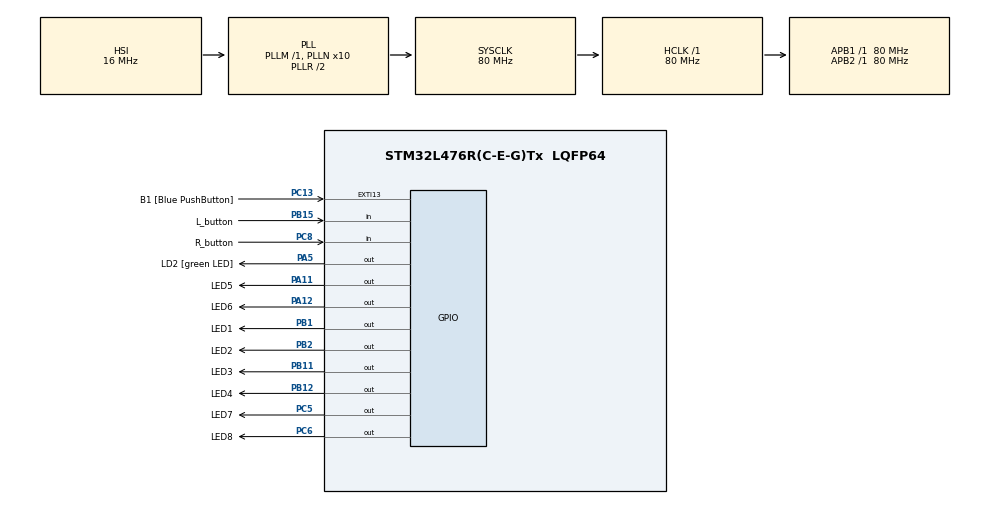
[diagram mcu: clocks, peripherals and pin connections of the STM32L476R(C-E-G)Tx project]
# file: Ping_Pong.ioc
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Mcu.Family=STM32L4
Mcu.Name=STM32L476R(C-E-G)Tx
Mcu.Package=LQFP64
NVIC.PriorityGroup=NVIC_PRIORITYGROUP_4
PA11.GPIO_Label=LED5
PA11.Signal=GPIO_Output
PA12.GPIO_Label=LED6
PA12.Signal=GPIO_Output
PA13\ (JTMS-SWDIO).GPIO_Label=TMS
PA13\ (JTMS-SWDIO).Signal=SYS_JTMS-SWDIO
PA14\ (JTCK-SWCLK).GPIO_Label=TCK
PA14\ (JTCK-SWCLK).Signal=SYS_JTCK-SWCLK
PA5.GPIO_Label=LD2 [green LED]
PA5.Signal=GPIO_Output
PB1.GPIO_Label=LED1
PB1.Signal=GPIO_Output
PB11.GPIO_Label=LED3
PB11.Signal=GPIO_Output
PB12.GPIO_Label=LED4
PB12.Signal=GPIO_Output
PB15.GPIO_Label=L_button
PB15.GPIO_PuPd=GPIO_PULLUP
PB15.Signal=GPIO_Input
PB2.GPIO_Label=LED2
PB2.Signal=GPIO_Output
PB3\ (JTDO-TRACESWO).GPIO_Label=SWD
PB3\ (JTDO-TRACESWO).Signal=SYS_JTDO-SWO
PC13.GPIO_Label=B1 [Blue PushButton]
PC13.Signal=GPXTI13
PC14-OSC32_IN\ (PC14).Mode=LSE-External-Oscillator
PC14-OSC32_IN\ (PC14).Signal=RCC_OSC32_IN
PC15-OSC32_OUT\ (PC15).Mode=LSE-External-Oscillator
PC15-OSC32_OUT\ (PC15).Signal=RCC_OSC32_OUT
PC5.GPIO_Label=LED7
PC5.Signal=GPIO_Output
PC6.GPIO_Label=LED8
PC6.Signal=GPIO_Output
PC8.GPIO_Label=R_button
PC8.GPIO_PuPd=GPIO_PULLUP
PC8.Signal=GPIO_Input
PH0-OSC_IN\ (PH0).Mode=HSE-External-Oscillator
PH0-OSC_IN\ (PH0).Signal=RCC_OSC_IN
PH1-OSC_OUT\ (PH1).Mode=HSE-External-Oscillator
PH1-OSC_OUT\ (PH1).Signal=RCC_OSC_OUT
ProjectManager.HeapSize=0x200
ProjectManager.StackSize=0x400
ProjectManager.TargetToolchain=STM32CubeIDE
RCC.ADCFreq_Value=64000000
RCC.AHBFreq_Value=80000000
RCC.APB1Freq_Value=80000000
RCC.APB1TimFreq_Value=80000000
RCC.APB2Freq_Value=80000000
RCC.APB2TimFreq_Value=80000000
RCC.CortexFreq_Value=80000000
RCC.HCLKFreq_Value=80000000
RCC.HSE_VALUE=8000000
RCC.HSI_VALUE=16000000
RCC.MSI_VALUE=4000000
RCC.PLLN=10
RCC.PLLSourceVirtual=RCC_PLLSOURCE_HSI
RCC.SYSCLKFreq_VALUE=80000000
RCC.SYSCLKSource=RCC_SYSCLKSOURCE_PLLCLK
RCC.USBFreq_Value=64000000
RCC.VCOOutputFreq_Value=160000000
board=custom

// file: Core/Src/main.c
/* USER CODE BEGIN Header */
/**
  ******************************************************************************
  * @file           : main.c
  * @brief          : Main program body
  ******************************************************************************
  * @attention
  *
  * Copyright (c) 2024 STMicroelectronics.
  * All rights reserved.
  *
  * This software is licensed under terms that can be found in the LICENSE file
  * in the root directory of this software component.
  * If no LICENSE file comes with this software, it is provided AS-IS.
  *
  ******************************************************************************
  */
/* USER CODE END Header */
#include "main.h"
#include "gpio.h"

/* USER CODE BEGIN Includes */
#include "Pingpong.h"
#include "pingpong_functions.h"
#include "Test.h"
#include <stdbool.h>
/* USER CODE END Includes */

/* USER CODE BEGIN PD */
#define RUN_TEST_PROGRAM
/* USER CODE END PD */

void SystemClock_Config(void);

/* USER CODE BEGIN 0 */
#ifdef Run_TEST_PROGRAM
extern void initialise_monitor_handles(void);
#endif
/* USER CODE END 0 */

int main(void)
{

  /* USER CODE BEGIN 1 */
#undef RUN_TEST_PROGRAM
  /* USER CODE END 1 */

  /* MCU Configuration--------------------------------------------------------*/

  /* Reset of all peripherals, Initializes the Flash interface and the Systick. */
  HAL_Init();

  /* Configure the system clock */
  SystemClock_Config();

  /* Initialize all configured peripherals */
  MX_GPIO_Init();
  /* USER CODE BEGIN 2 */
#ifdef RUN_TEST_PROGRAM
  Test_program();
#else
  Pingpong();
#endif
  /* USER CODE END 2 */

  /* Infinite loop */
  while (1)
  {
	  HAL_GPIO_WritePin(LED1_GPIO_Port, LED1_Pin, GPIO_PIN_SET); // Led 1
	  HAL_Delay(50);
	  HAL_GPIO_WritePin(LED1_GPIO_Port, LED1_Pin, GPIO_PIN_RESET);
	  HAL_GPIO_WritePin(LED2_GPIO_Port, LED2_Pin, GPIO_PIN_SET); // Led 2
	  HAL_Delay(50);
	  HAL_GPIO_WritePin(LED2_GPIO_Port, LED2_Pin, GPIO_PIN_RESET);
	  HAL_GPIO_WritePin(LED3_GPIO_Port, LED3_Pin, GPIO_PIN_SET); // Led 3
	  HAL_Delay(50);
	  HAL_GPIO_WritePin(LED3_GPIO_Port, LED3_Pin, GPIO_PIN_RESET);
	  HAL_GPIO_WritePin(LED4_GPIO_Port, LED4_Pin, GPIO_PIN_SET); // Led 4
	  HAL_Delay(50);
	  HAL_GPIO_WritePin(LED4_GPIO_Port, LED4_Pin, GPIO_PIN_RESET);
	  HAL_GPIO_WritePin(LED5_GPIO_Port, LED5_Pin, GPIO_PIN_SET); // Led 5
	  HAL_Delay(50);
	  HAL_GPIO_WritePin(LED5_GPIO_Port, LED5_Pin, GPIO_PIN_RESET);
	  HAL_GPIO_WritePin(LED6_GPIO_Port, LED6_Pin, GPIO_PIN_SET); // Led 6
	  HAL_Delay(50);
	  HAL_GPIO_WritePin(LED6_GPIO_Port, LED6_Pin, GPIO_PIN_RESET);
	  HAL_GPIO_WritePin(LED7_GPIO_Port, LED7_Pin, GPIO_PIN_SET); // Led 7
	  HAL_Delay(50);
	  HAL_GPIO_WritePin(LED7_GPIO_Port, LED7_Pin, GPIO_PIN_RESET);
	  HAL_GPIO_WritePin(LED8_GPIO_Port, LED8_Pin, GPIO_PIN_SET); // Led 8
	  HAL_Delay(50);
	  HAL_GPIO_WritePin(LED8_GPIO_Port, LED8_Pin, GPIO_PIN_RESET);
  }
}

void SystemClock_Config(void)
{
  RCC_OscInitTypeDef RCC_OscInitStruct = {0};
  RCC_ClkInitTypeDef RCC_ClkInitStruct = {0};

  /** Configure the main internal regulator output voltage
  */
  if (HAL_PWREx_ControlVoltageScaling(PWR_REGULATOR_VOLTAGE_SCALE1) != HAL_OK)
  {
    Error_Handler();
  }

  /** Initializes the RCC Oscillators according to the specified parameters
  * in the RCC_OscInitTypeDef structure.
  */
  RCC_OscInitStruct.OscillatorType = RCC_OSCILLATORTYPE_HSI;
  RCC_OscInitStruct.HSIState = RCC_HSI_ON;
  RCC_OscInitStruct.HSICalibrationValue = RCC_HSICALIBRATION_DEFAULT;
  RCC_OscInitStruct.PLL.PLLState = RCC_PLL_ON;
  RCC_OscInitStruct.PLL.PLLSource = RCC_PLLSOURCE_HSI;
  RCC_OscInitStruct.PLL.PLLM = 1;
  RCC_OscInitStruct.PLL.PLLN = 10;
  RCC_OscInitStruct.PLL.PLLP = RCC_PLLP_DIV7;
  RCC_OscInitStruct.PLL.PLLQ = RCC_PLLQ_DIV2;
  RCC_OscInitStruct.PLL.PLLR = RCC_PLLR_DIV2;
  if (HAL_RCC_OscConfig(&RCC_OscInitStruct) != HAL_OK)
  {
    Error_Handler();
  }

  /** Initializes the CPU, AHB and APB buses clocks
  */
  RCC_ClkInitStruct.ClockType = RCC_CLOCKTYPE_HCLK|RCC_CLOCKTYPE_SYSCLK
                              |RCC_CLOCKTYPE_PCLK1|RCC_CLOCKTYPE_PCLK2;
  RCC_ClkInitStruct.SYSCLKSource = RCC_SYSCLKSOURCE_PLLCLK;
  RCC_ClkInitStruct.AHBCLKDivider = RCC_SYSCLK_DIV1;
  RCC_ClkInitStruct.APB1CLKDivider = RCC_HCLK_DIV1;
  RCC_ClkInitStruct.APB2CLKDivider = RCC_HCLK_DIV1;

  if (HAL_RCC_ClockConfig(&RCC_ClkInitStruct, FLASH_LATENCY_4) != HAL_OK)
  {
    Error_Handler();
  }
}

void Error_Handler(void)
{
  __disable_irq();
  while (1)
  {
  }
}
